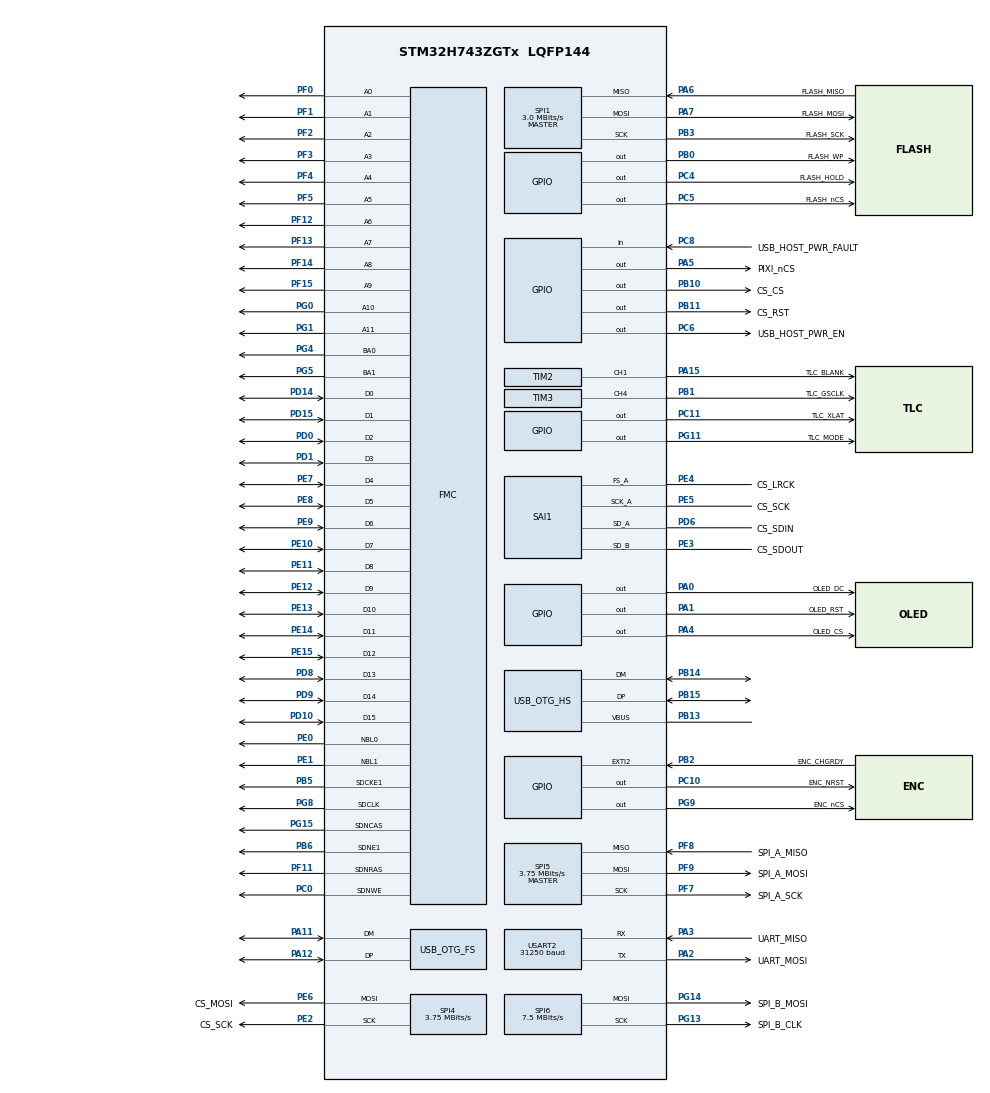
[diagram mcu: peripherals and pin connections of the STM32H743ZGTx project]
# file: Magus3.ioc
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Bdma.Request0=SPI6_TX
Bdma.RequestsNb=1
Bdma.SPI6_TX.0.Direction=DMA_MEMORY_TO_PERIPH
Bdma.SPI6_TX.0.EventEnable=DISABLE
Bdma.SPI6_TX.0.Instance=BDMA_Channel0
Bdma.SPI6_TX.0.MemDataAlignment=DMA_MDATAALIGN_BYTE
Bdma.SPI6_TX.0.MemInc=DMA_MINC_ENABLE
Bdma.SPI6_TX.0.Mode=DMA_NORMAL
Bdma.SPI6_TX.0.PeriphDataAlignment=DMA_PDATAALIGN_BYTE
Bdma.SPI6_TX.0.PeriphInc=DMA_PINC_DISABLE
Bdma.SPI6_TX.0.Polarity=HAL_DMAMUX_REQ_GEN_RISING
Bdma.SPI6_TX.0.Priority=DMA_PRIORITY_LOW
Bdma.SPI6_TX.0.RequestNumber=1
Bdma.SPI6_TX.0.SignalID=NONE
Bdma.SPI6_TX.0.SyncEnable=DISABLE
Bdma.SPI6_TX.0.SyncPolarity=HAL_DMAMUX_SYNC_NO_EVENT
Bdma.SPI6_TX.0.SyncRequestNumber=1
Bdma.SPI6_TX.0.SyncSignalID=NONE
Dma.Request0=SAI1_A
Dma.Request1=SAI1_B
Dma.Request2=SPI5_TX
Dma.Request3=USART2_TX
Dma.Request4=USART2_RX
Dma.SAI1_A.0.Direction=DMA_MEMORY_TO_PERIPH
Dma.SAI1_A.0.EventEnable=DISABLE
Dma.SAI1_A.0.FIFOMode=DMA_FIFOMODE_DISABLE
Dma.SAI1_A.0.Instance=DMA2_Stream1
Dma.SAI1_A.0.MemDataAlignment=DMA_MDATAALIGN_WORD
Dma.SAI1_A.0.MemInc=DMA_MINC_ENABLE
Dma.SAI1_A.0.Mode=DMA_CIRCULAR
Dma.SAI1_A.0.PeriphDataAlignment=DMA_PDATAALIGN_WORD
Dma.SAI1_A.0.PeriphInc=DMA_PINC_DISABLE
Dma.SAI1_A.0.Polarity=HAL_DMAMUX_REQ_GEN_RISING
Dma.SAI1_A.0.Priority=DMA_PRIORITY_VERY_HIGH
Dma.SAI1_A.0.RequestNumber=1
Dma.SAI1_A.0.SignalID=NONE
Dma.SAI1_A.0.SyncEnable=DISABLE
Dma.SAI1_A.0.SyncPolarity=HAL_DMAMUX_SYNC_NO_EVENT
Dma.SAI1_A.0.SyncRequestNumber=1
Dma.SAI1_A.0.SyncSignalID=NONE
Dma.SAI1_B.1.Direction=DMA_PERIPH_TO_MEMORY
Dma.SAI1_B.1.EventEnable=DISABLE
Dma.SAI1_B.1.FIFOMode=DMA_FIFOMODE_DISABLE
Dma.SAI1_B.1.Instance=DMA2_Stream4
Dma.SAI1_B.1.MemDataAlignment=DMA_MDATAALIGN_WORD
Dma.SAI1_B.1.MemInc=DMA_MINC_ENABLE
Dma.SAI1_B.1.Mode=DMA_CIRCULAR
Dma.SAI1_B.1.PeriphDataAlignment=DMA_PDATAALIGN_WORD
Dma.SAI1_B.1.PeriphInc=DMA_PINC_DISABLE
Dma.SAI1_B.1.Polarity=HAL_DMAMUX_REQ_GEN_RISING
Dma.SAI1_B.1.Priority=DMA_PRIORITY_VERY_HIGH
Dma.SAI1_B.1.RequestNumber=1
Dma.SAI1_B.1.SignalID=NONE
Dma.SAI1_B.1.SyncEnable=DISABLE
Dma.SAI1_B.1.SyncPolarity=HAL_DMAMUX_SYNC_NO_EVENT
Dma.SAI1_B.1.SyncRequestNumber=1
Dma.SAI1_B.1.SyncSignalID=NONE
Dma.SPI5_TX.2.Direction=DMA_MEMORY_TO_PERIPH
Dma.SPI5_TX.2.EventEnable=DISABLE
Dma.SPI5_TX.2.FIFOMode=DMA_FIFOMODE_DISABLE
Dma.SPI5_TX.2.Instance=DMA2_Stream6
Dma.SPI5_TX.2.MemDataAlignment=DMA_MDATAALIGN_BYTE
Dma.SPI5_TX.2.MemInc=DMA_MINC_ENABLE
Dma.SPI5_TX.2.Mode=DMA_NORMAL
Dma.SPI5_TX.2.PeriphDataAlignment=DMA_PDATAALIGN_BYTE
Dma.SPI5_TX.2.PeriphInc=DMA_PINC_DISABLE
Dma.SPI5_TX.2.Polarity=HAL_DMAMUX_REQ_GEN_RISING
Dma.SPI5_TX.2.Priority=DMA_PRIORITY_LOW
Dma.SPI5_TX.2.RequestNumber=1
Dma.SPI5_TX.2.SignalID=NONE
Dma.SPI5_TX.2.SyncEnable=DISABLE
Dma.SPI5_TX.2.SyncPolarity=HAL_DMAMUX_SYNC_NO_EVENT
Dma.SPI5_TX.2.SyncRequestNumber=1
Dma.SPI5_TX.2.SyncSignalID=NONE
Dma.USART2_RX.4.Direction=DMA_PERIPH_TO_MEMORY
Dma.USART2_RX.4.EventEnable=DISABLE
Dma.USART2_RX.4.FIFOMode=DMA_FIFOMODE_DISABLE
Dma.USART2_RX.4.Instance=DMA1_Stream5
Dma.USART2_RX.4.MemDataAlignment=DMA_MDATAALIGN_BYTE
Dma.USART2_RX.4.MemInc=DMA_MINC_ENABLE
Dma.USART2_RX.4.Mode=DMA_NORMAL
Dma.USART2_RX.4.PeriphDataAlignment=DMA_PDATAALIGN_BYTE
Dma.USART2_RX.4.PeriphInc=DMA_PINC_DISABLE
Dma.USART2_RX.4.Polarity=HAL_DMAMUX_REQ_GEN_RISING
Dma.USART2_RX.4.Priority=DMA_PRIORITY_LOW
Dma.USART2_RX.4.RequestNumber=1
Dma.USART2_RX.4.SignalID=NONE
Dma.USART2_RX.4.SyncEnable=DISABLE
Dma.USART2_RX.4.SyncPolarity=HAL_DMAMUX_SYNC_NO_EVENT
Dma.USART2_RX.4.SyncRequestNumber=1
Dma.USART2_RX.4.SyncSignalID=NONE
Dma.USART2_TX.3.Direction=DMA_MEMORY_TO_PERIPH
Dma.USART2_TX.3.EventEnable=DISABLE
Dma.USART2_TX.3.FIFOMode=DMA_FIFOMODE_DISABLE
Dma.USART2_TX.3.Instance=DMA1_Stream6
Dma.USART2_TX.3.MemDataAlignment=DMA_MDATAALIGN_BYTE
Dma.USART2_TX.3.MemInc=DMA_MINC_ENABLE
Dma.USART2_TX.3.Mode=DMA_NORMAL
Dma.USART2_TX.3.PeriphDataAlignment=DMA_PDATAALIGN_BYTE
Dma.USART2_TX.3.PeriphInc=DMA_PINC_DISABLE
Dma.USART2_TX.3.Polarity=HAL_DMAMUX_REQ_GEN_RISING
Dma.USART2_TX.3.Priority=DMA_PRIORITY_LOW
Dma.USART2_TX.3.RequestNumber=1
Dma.USART2_TX.3.SignalID=NONE
Dma.USART2_TX.3.SyncEnable=DISABLE
Dma.USART2_TX.3.SyncPolarity=HAL_DMAMUX_SYNC_NO_EVENT
Dma.USART2_TX.3.SyncRequestNumber=1
Dma.USART2_TX.3.SyncSignalID=NONE
FMC.CASLatency1=FMC_SDRAM_CAS_LATENCY_3
FMC.ExitSelfRefreshDelay1=6
FMC.LoadToActiveDelay1=2
FMC.RCDDelay1=2
FMC.RPDelay1=2
FMC.RPDelay2=2
FMC.ReadBurst1=FMC_SDRAM_RBURST_ENABLE
FMC.ReadBurst2=FMC_SDRAM_RBURST_ENABLE
FMC.ReadPipeDelay1=FMC_SDRAM_RPIPE_DELAY_0
FMC.RowCycleDelay1=6
FMC.RowCycleDelay2=6
FMC.SDClockPeriod1=FMC_SDRAM_CLOCK_PERIOD_2
FMC.SDClockPeriod2=FMC_SDRAM_CLOCK_PERIOD_2
FMC.SelfRefreshTime1=4
FMC.WriteRecoveryTime1=2
FREERTOS.INCLUDE_vTaskDelayUntil=1
FREERTOS.MEMORY_ALLOCATION=2
FREERTOS.Tasks01=defaultTask,0,1024,StartDefaultTask,Default,NULL,Dynamic,NULL,NULL
FREERTOS.configCHECK_FOR_STACK_OVERFLOW=2
FREERTOS.configUSE_MALLOC_FAILED_HOOK=1
FREERTOS.configUSE_MUTEXES=0
FREERTOS.configUSE_PREEMPTION=0
Mcu.Family=STM32H7
Mcu.Name=STM32H743ZGTx
Mcu.Package=LQFP144
NVIC.BDMA_Channel0_IRQn=true\:5\:0\:false\:false\:true\:true\:false\:true
NVIC.DMA1_Stream5_IRQn=true\:5\:0\:false\:false\:true\:true\:false\:true
NVIC.DMA1_Stream6_IRQn=true\:5\:0\:false\:false\:true\:true\:false\:true
NVIC.DMA2_Stream1_IRQn=true\:5\:0\:true\:false\:true\:true\:true\:true
NVIC.DMA2_Stream4_IRQn=true\:5\:0\:true\:false\:true\:true\:true\:true
NVIC.DMA2_Stream6_IRQn=true\:5\:0\:false\:false\:true\:true\:false\:true
NVIC.EXTI2_IRQn=true\:5\:0\:false\:false\:true\:true\:true\:true
NVIC.OTG_FS_IRQn=true\:10\:0\:true\:false\:true\:true\:true\:true
NVIC.OTG_HS_IRQn=true\:10\:0\:true\:false\:true\:true\:true\:true
NVIC.PriorityGroup=NVIC_PRIORITYGROUP_4
NVIC.SPI5_IRQn=true\:10\:0\:true\:false\:true\:true\:true\:true
NVIC.SPI6_IRQn=true\:5\:0\:false\:false\:true\:true\:true\:true
NVIC.USART2_IRQn=true\:5\:0\:false\:false\:true\:true\:true\:true
PA0.GPIO_Label=OLED_DC
PA0.Signal=GPIO_Output
PA1.GPIO_Label=OLED_RST
PA1.Signal=GPIO_Output
PA11.Mode=Device_Only
PA11.Signal=USB_OTG_FS_DM
PA12.Mode=Device_Only
PA12.Signal=USB_OTG_FS_DP
PA13\ (JTMS/SWDIO).Mode=Serial_Wire
PA13\ (JTMS/SWDIO).Signal=DEBUG_JTMS-SWDIO
PA14\ (JTCK/SWCLK).Mode=Serial_Wire
PA14\ (JTCK/SWCLK).Signal=DEBUG_JTCK-SWCLK
PA15\ (JTDI).GPIO_Label=TLC_BLANK
PA15\ (JTDI).GPIO_Speed=GPIO_SPEED_FREQ_VERY_HIGH
PA15\ (JTDI).Signal=S_TIM2_CH1
PA2.GPIO_Label=UART_MOSI
PA2.GPIO_Speed=GPIO_SPEED_FREQ_MEDIUM
PA2.Mode=Asynchronous
PA2.Signal=USART2_TX
PA3.GPIO_Label=UART_MISO
PA3.GPIO_Speed=GPIO_SPEED_FREQ_MEDIUM
PA3.Mode=Asynchronous
PA3.Signal=USART2_RX
PA4.GPIO_Label=OLED_CS
PA4.Signal=GPIO_Output
PA5.GPIO_Label=PIXI_nCS
PA5.Signal=GPIO_Output
PA6.GPIO_Label=FLASH_MISO
PA6.GPIO_Speed=GPIO_SPEED_FREQ_VERY_HIGH
PA6.Mode=Full_Duplex_Master
PA6.Signal=SPI1_MISO
PA7.GPIO_Label=FLASH_MOSI
PA7.GPIO_Speed=GPIO_SPEED_FREQ_VERY_HIGH
PA7.Mode=Full_Duplex_Master
PA7.Signal=SPI1_MOSI
PB0.GPIO_Label=FLASH_WP
PB0.Signal=GPIO_Output
PB1.GPIO_Label=TLC_GSCLK
PB1.GPIO_Speed=GPIO_SPEED_FREQ_VERY_HIGH
PB1.Signal=S_TIM3_CH4
PB10.GPIO_Label=CS_CS
PB10.Signal=GPIO_Output
PB11.GPIO_Label=CS_RST
PB11.Signal=GPIO_Output
PB13.Mode=Activate_VBUS_FS
PB13.Signal=USB_OTG_HS_VBUS
PB14.Mode=Host_FS
PB14.Signal=USB_OTG_HS_DM
PB15.Mode=Host_FS
PB15.Signal=USB_OTG_HS_DP
PB2.GPIO_Label=ENC_CHGRDY
PB2.Signal=GPXTI2
PB3\ (JTDO/TRACESWO).GPIO_Label=FLASH_SCK
PB3\ (JTDO/TRACESWO).GPIO_Speed=GPIO_SPEED_FREQ_VERY_HIGH
PB3\ (JTDO/TRACESWO).Mode=Full_Duplex_Master
PB3\ (JTDO/TRACESWO).Signal=SPI1_SCK
PB5.Mode=SdramChipSelect2_1
PB5.Signal=FMC_SDCKE1
PB6.Mode=SdramChipSelect2_1
PB6.Signal=FMC_SDNE1
PC0.Signal=FMC_SDNWE
PC10.GPIO_Label=ENC_NRST
PC10.GPIO_PuPd=GPIO_PULLUP
PC10.Signal=GPIO_Output
PC11.GPIO_Label=TLC_XLAT
PC11.Signal=GPIO_Output
PC4.GPIO_Label=FLASH_HOLD
PC4.Signal=GPIO_Output
PC5.GPIO_Label=FLASH_nCS
PC5.Signal=GPIO_Output
PC6.GPIO_Label=USB_HOST_PWR_EN
PC6.PinState=GPIO_PIN_SET
PC6.Signal=GPIO_Output
PC8.GPIO_Label=USB_HOST_PWR_FAULT
PC8.GPIO_PuPd=GPIO_PULLUP
PC8.Signal=GPIO_Input
PD0.Signal=FMC_D2_DA2
PD1.Signal=FMC_D3_DA3
PD10.Signal=FMC_D15_DA15
PD14.Signal=FMC_D0_DA0
PD15.Signal=FMC_D1_DA1
PD6.GPIO_Label=CS_SDIN
PD6.Mode=SAI_A_AsyncSlave
PD6.Signal=SAI1_SD_A
PD8.Signal=FMC_D13_DA13
PD9.Signal=FMC_D14_DA14
PE0.Signal=FMC_NBL0
PE1.Signal=FMC_NBL1
PE10.Signal=FMC_D7_DA7
PE11.Signal=FMC_D8_DA8
PE12.Signal=FMC_D9_DA9
PE13.Signal=FMC_D10_DA10
PE14.Signal=FMC_D11_DA11
PE15.Signal=FMC_D12_DA12
PE2.GPIO_Label=CS_SCK
PE2.Mode=TX_Only_Simplex_Unidirect_Master
PE2.Signal=SPI4_SCK
PE3.GPIO_Label=CS_SDOUT
PE3.Mode=SAI_B_SyncSlave
PE3.Signal=SAI1_SD_B
PE4.GPIO_Label=CS_LRCK
PE4.Mode=SAI_A_AsyncSlave
PE4.Signal=SAI1_FS_A
PE5.GPIO_Label=CS_SCK
PE5.Mode=SAI_A_AsyncSlave
PE5.Signal=SAI1_SCK_A
PE6.GPIO_Label=CS_MOSI
PE6.Mode=TX_Only_Simplex_Unidirect_Master
PE6.Signal=SPI4_MOSI
PE7.Signal=FMC_D4_DA4
PE8.Signal=FMC_D5_DA5
PE9.Signal=FMC_D6_DA6
PF0.Signal=FMC_A0
PF1.Signal=FMC_A1
PF11.Signal=FMC_SDNRAS
PF12.Signal=FMC_A6
PF13.Signal=FMC_A7
PF14.Signal=FMC_A8
PF15.Signal=FMC_A9
PF2.Signal=FMC_A2
PF3.Signal=FMC_A3
PF4.Signal=FMC_A4
PF5.Signal=FMC_A5
PF7.GPIO_Label=SPI_A_SCK
PF7.GPIO_Speed=GPIO_SPEED_FREQ_VERY_HIGH
PF7.Mode=Full_Duplex_Master
PF7.Signal=SPI5_SCK
PF8.GPIO_Label=SPI_A_MISO
PF8.GPIO_Speed=GPIO_SPEED_FREQ_VERY_HIGH
PF8.Mode=Full_Duplex_Master
PF8.Signal=SPI5_MISO
PF9.GPIO_Label=SPI_A_MOSI
PF9.GPIO_Speed=GPIO_SPEED_FREQ_VERY_HIGH
PF9.Mode=Full_Duplex_Master
PF9.Signal=SPI5_MOSI
PG0.Signal=FMC_A10
PG1.Signal=FMC_A11
PG11.GPIO_Label=TLC_MODE
PG11.Signal=GPIO_Output
PG13.GPIO_Label=SPI_B_CLK
PG13.Mode=TX_Only_Simplex_Unidirect_Master
PG13.Signal=SPI6_SCK
PG14.GPIO_Label=SPI_B_MOSI
PG14.Mode=TX_Only_Simplex_Unidirect_Master
PG14.Signal=SPI6_MOSI
PG15.Signal=FMC_SDNCAS
PG4.Signal=FMC_A14_BA0
PG5.Signal=FMC_A15_BA1
PG8.Signal=FMC_SDCLK
PG9.GPIO_Label=ENC_nCS
PG9.Signal=GPIO_Output
PH0-OSC_IN\ (PH0).GPIO_Label=OSC1
PH0-OSC_IN\ (PH0).Mode=HSE-External-Oscillator
PH0-OSC_IN\ (PH0).Signal=RCC_OSC_IN
PH1-OSC_OUT\ (PH1).GPIO_Label=OSC2
PH1-OSC_OUT\ (PH1).Mode=HSE-External-Oscillator
PH1-OSC_OUT\ (PH1).Signal=RCC_OSC_OUT
ProjectManager.HeapSize=0x200
ProjectManager.StackSize=0x400
ProjectManager.TargetToolchain=Other Toolchains (GPDSC)
RCC.48MHZClocksFreq_Value=48000000
RCC.ADCFreq_Value=30000000
RCC.AHBFreq_Value=168000000
RCC.APB1CLKDivider=RCC_HCLK_DIV4
RCC.APB1Freq_Value=120000000
RCC.APB1TimFreq_Value=84000000
RCC.APB2CLKDivider=RCC_HCLK_DIV2
RCC.APB2Freq_Value=120000000
RCC.APB2TimFreq_Value=168000000
RCC.APB3Freq_Value=120000000
RCC.APB4Freq_Value=120000000
RCC.CortexFreq_Value=480000000
RCC.D1PPRE=RCC_APB3_DIV2
RCC.D2PPRE1=RCC_APB1_DIV2
RCC.D2PPRE2=RCC_APB2_DIV2
RCC.D3PPRE=RCC_APB4_DIV2
RCC.DIVM1=5
RCC.DIVM2=2
RCC.DIVN1=192
RCC.DIVN2=12
RCC.DIVP2=5
RCC.DIVQ1=20
RCC.HCLKFreq_Value=240000000
RCC.HPRE=RCC_HCLK_DIV2
RCC.HSE_VALUE=25000000
RCC.HSI_VALUE=16000000
RCC.LSE_VALUE=32768
RCC.PLLM=25
RCC.PLLN=336
RCC.PLLQ=7
RCC.PLLSAIN=100
RCC.PWR_Regulator_Voltage_Scale=PWR_REGULATOR_VOLTAGE_SCALE0
RCC.ProductRev=revV
RCC.SAI1CLockSelection=RCC_SAI1CLKSOURCE_PLL2
RCC.SYSCLKFreq_VALUE=480000000
RCC.SYSCLKSource=RCC_SYSCLKSOURCE_PLLCLK
RCC.USBFreq_Value=48000000
RCC.VCOOutputFreq_Value=336000000
SAI1.AudioMode-SAI_A_AsyncSlave=SAI_MODESLAVE_TX
SAI1.AudioMode-SAI_B_SyncSlave=SAI_MODESLAVE_RX
SAI1.BasicDataSize-SAI_A_AsyncSlave=SAI_PROTOCOL_DATASIZE_24BIT
SAI1.BasicDataSize-SAI_B_SyncSlave=SAI_PROTOCOL_DATASIZE_24BIT
SAI1.InitProtocol-SAI_A_AsyncSlave=Enable
SAI1.InitProtocol-SAI_B_SyncSlave=Enable
SAI1.Instance-SAI_A_AsyncSlave=SAI$Index_Block_A
SAI1.Instance-SAI_B_SyncSlave=SAI$Index_Block_B
SAI1.Synchro_A=SAI_ASYNCHRONOUS
SAI1.Synchro_B=SAI_SYNCHRONOUS
SAI1.VirtualMode-SAI_A_AsyncSlave=VM_SLAVE
SAI1.VirtualMode-SAI_B_SyncSlave=VM_SLAVE
SAI1.VirtualProtocol-SAI_A_BASIC=VM_BASIC_PROTOCOL
SAI1.VirtualProtocol-SAI_B_BASIC=VM_BASIC_PROTOCOL
SH.FMC_A0.0=FMC_A0,12b-sda1
SH.FMC_A1.0=FMC_A1,12b-sda1
SH.FMC_A10.0=FMC_A10,12b-sda1
SH.FMC_A11.0=FMC_A11,12b-sda1
SH.FMC_A14_BA0.0=FMC_BA0,FourSdramBanks1
SH.FMC_A15_BA1.0=FMC_BA1,FourSdramBanks1
SH.FMC_A2.0=FMC_A2,12b-sda1
SH.FMC_A3.0=FMC_A3,12b-sda1
SH.FMC_A4.0=FMC_A4,12b-sda1
SH.FMC_A5.0=FMC_A5,12b-sda1
SH.FMC_A6.0=FMC_A6,12b-sda1
SH.FMC_A7.0=FMC_A7,12b-sda1
SH.FMC_A8.0=FMC_A8,12b-sda1
SH.FMC_A9.0=FMC_A9,12b-sda1
SH.FMC_D0_DA0.0=FMC_D0,sd-16b-d1
SH.FMC_D10_DA10.0=FMC_D10,sd-16b-d1
SH.FMC_D11_DA11.0=FMC_D11,sd-16b-d1
SH.FMC_D12_DA12.0=FMC_D12,sd-16b-d1
SH.FMC_D13_DA13.0=FMC_D13,sd-16b-d1
SH.FMC_D14_DA14.0=FMC_D14,sd-16b-d1
SH.FMC_D15_DA15.0=FMC_D15,sd-16b-d1
SH.FMC_D1_DA1.0=FMC_D1,sd-16b-d1
SH.FMC_D2_DA2.0=FMC_D2,sd-16b-d1
SH.FMC_D3_DA3.0=FMC_D3,sd-16b-d1
SH.FMC_D4_DA4.0=FMC_D4,sd-16b-d1
SH.FMC_D5_DA5.0=FMC_D5,sd-16b-d1
SH.FMC_D6_DA6.0=FMC_D6,sd-16b-d1
SH.FMC_D7_DA7.0=FMC_D7,sd-16b-d1
SH.FMC_D8_DA8.0=FMC_D8,sd-16b-d1
SH.FMC_D9_DA9.0=FMC_D9,sd-16b-d1
SH.FMC_NBL0.0=FMC_NBL0,Sd2ByteEnable1
SH.FMC_NBL1.0=FMC_NBL1,Sd2ByteEnable1
SH.FMC_SDCLK.0=FMC_SDCLK,12b-sda1
SH.FMC_SDNCAS.0=FMC_SDNCAS,12b-sda1
SH.FMC_SDNRAS.0=FMC_SDNRAS,12b-sda1
SH.FMC_SDNWE.0=FMC_SDNWE,12b-sda1
SH.S_TIM2_CH1.0=TIM2_CH1,PWM Generation1 CH1
SH.S_TIM3_CH4.0=TIM3_CH4,PWM Generation4 CH4
SPI1.BaudRatePrescaler=SPI_BAUDRATEPRESCALER_16
SPI1.CalculateBaudRate=3.0 MBits/s
SPI1.DataSize=SPI_DATASIZE_8BIT
SPI1.Direction=SPI_DIRECTION_2LINES
SPI1.Mode=SPI_MODE_MASTER
SPI1.NSSPMode=SPI_NSS_PULSE_DISABLE
SPI1.VirtualType=VM_MASTER
SPI4.BaudRatePrescaler=SPI_BAUDRATEPRESCALER_32
SPI4.CalculateBaudRate=3.75 MBits/s
SPI4.DataSize=SPI_DATASIZE_8BIT
SPI4.Direction=SPI_DIRECTION_2LINES_TXONLY
SPI4.Mode=SPI_MODE_MASTER
SPI4.NSSPMode=SPI_NSS_PULSE_DISABLE
SPI4.VirtualType=VM_MASTER
SPI5.BaudRatePrescaler=SPI_BAUDRATEPRESCALER_32
SPI5.CalculateBaudRate=3.75 MBits/s
SPI5.DataSize=SPI_DATASIZE_8BIT
SPI5.Direction=SPI_DIRECTION_2LINES
SPI5.Mode=SPI_MODE_MASTER
SPI5.NSSPMode=SPI_NSS_PULSE_DISABLE
SPI5.VirtualType=VM_MASTER
SPI6.BaudRatePrescaler=SPI_BAUDRATEPRESCALER_16
SPI6.CalculateBaudRate=7.5 MBits/s
SPI6.DataSize=SPI_DATASIZE_8BIT
SPI6.Direction=SPI_DIRECTION_2LINES_TXONLY
SPI6.Mode=SPI_MODE_MASTER
SPI6.NSSPMode=SPI_NSS_PULSE_DISABLE
SPI6.VirtualType=VM_MASTER
TIM2.Channel-PWM\ Generation1\ CH1=TIM_CHANNEL_1
TIM2.ClockDivision=TIM_CLOCKDIVISION_DIV2
TIM2.Period=200
TIM2.Prescaler=4095
TIM2.Pulse-PWM\ Generation1\ CH1=100
TIM3.Channel-PWM\ Generation4\ CH4=TIM_CHANNEL_4
TIM3.ClockDivision=TIM_CLOCKDIVISION_DIV2
TIM3.OCFastMode_PWM-PWM\ Generation4\ CH4=TIM_OCFAST_DISABLE
TIM3.Period=100
TIM3.Pulse-PWM\ Generation4\ CH4=50
USART2.BaudRate=31250
USART2.Mode=MODE_TX_RX
USART2.VirtualMode=VM_ASYNC
USART2.VirtualMode-Asynchronous=VM_ASYNC
USB_OTG_FS.VirtualMode=Device_Only
USB_OTG_HS.VirtualMode-Host_FS=Host_FS
VP_FREERTOS_VS_CMSIS_V1.Mode=CMSIS_V1
VP_SAI1_VP_$IpInstance_SAIA_SAI_BASIC.Mode=SAI_A_BASIC
VP_SAI1_VP_$IpInstance_SAIB_SAI_BASIC.Mode=SAI_B_BASIC
board=Magus

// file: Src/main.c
/* USER CODE BEGIN Header */
/**
  ******************************************************************************
  * @file           : main.c
  * @brief          : Main program body
  ******************************************************************************
  * This notice applies to any and all portions of this file
  * that are not between comment pairs USER CODE BEGIN and
  * USER CODE END. Other portions of this file, whether
  * inserted by the user or by software development tools
  * are owned by their respective copyright owners.
  *
  * Copyright (c) 2018 STMicroelectronics International N.V.
  * All rights reserved.
  *
  * Redistribution and use in source and binary forms, with or without
  * modification, are permitted, provided that the following conditions are met:
  *
  * 1. Redistribution of source code must retain the above copyright notice,
  *    this list of conditions and the following disclaimer.
  * 2. Redistributions in binary form must reproduce the above copyright notice,
  *    this list of conditions and the following disclaimer in the documentation
  *    and/or other materials provided with the distribution.
  * 3. Neither the name of STMicroelectronics nor the names of other
  *    contributors to this software may be used to endorse or promote products
  *    derived from this software without specific written permission.
  * 4. This software, including modifications and/or derivative works of this
  *    software, must execute solely and exclusively on microcontroller or
  *    microprocessor devices manufactured by or for STMicroelectronics.
  * 5. Redistribution and use of this software other than as permitted under
  *    this license is void and will automatically terminate your rights under
  *    this license.
  *
  * THIS SOFTWARE IS PROVIDED BY STMICROELECTRONICS AND CONTRIBUTORS "AS IS"
  * AND ANY EXPRESS, IMPLIED OR STATUTORY WARRANTIES, INCLUDING, BUT NOT
  * LIMITED TO, THE IMPLIED WARRANTIES OF MERCHANTABILITY, FITNESS FOR A
  * PARTICULAR PURPOSE AND NON-INFRINGEMENT OF THIRD PARTY INTELLECTUAL PROPERTY
  * RIGHTS ARE DISCLAIMED TO THE FULLEST EXTENT PERMITTED BY LAW. IN NO EVENT
  * SHALL STMICROELECTRONICS OR CONTRIBUTORS BE LIABLE FOR ANY DIRECT, INDIRECT,
  * INCIDENTAL, SPECIAL, EXEMPLARY, OR CONSEQUENTIAL DAMAGES (INCLUDING, BUT NOT
  * LIMITED TO, PROCUREMENT OF SUBSTITUTE GOODS OR SERVICES; LOSS OF USE, DATA,
  * OR PROFITS; OR BUSINESS INTERRUPTION) HOWEVER CAUSED AND ON ANY THEORY OF
  * LIABILITY, WHETHER IN CONTRACT, STRICT LIABILITY, OR TORT (INCLUDING
  * NEGLIGENCE OR OTHERWISE) ARISING IN ANY WAY OUT OF THE USE OF THIS SOFTWARE,
  * EVEN IF ADVISED OF THE POSSIBILITY OF SUCH DAMAGE.
  *
  ******************************************************************************
  */
/* USER CODE END Header */
#include "main.h"
#include "cmsis_os.h"

/* USER CODE BEGIN Includes */
#include "device.h"
#include "errorhandlers.h"
/* USER CODE END Includes */

SAI_HandleTypeDef hsai_BlockA1;
SAI_HandleTypeDef hsai_BlockB1;
DMA_HandleTypeDef hdma_sai1_a;
DMA_HandleTypeDef hdma_sai1_b;

SPI_HandleTypeDef hspi1;
SPI_HandleTypeDef hspi4;
SPI_HandleTypeDef hspi5;
SPI_HandleTypeDef hspi6;
DMA_HandleTypeDef hdma_spi5_tx;
DMA_HandleTypeDef hdma_spi6_tx;

TIM_HandleTypeDef htim2;
TIM_HandleTypeDef htim3;

UART_HandleTypeDef huart2;
DMA_HandleTypeDef hdma_usart2_tx;
DMA_HandleTypeDef hdma_usart2_rx;

PCD_HandleTypeDef hpcd_USB_OTG_FS;
HCD_HandleTypeDef hhcd_USB_OTG_HS;

SDRAM_HandleTypeDef hsdram1;

osThreadId defaultTaskHandle;
/* USER CODE BEGIN PV */
/* Private variables ---------------------------------------------------------*/
/* USER CODE END PV */

void SystemClock_Config(void);
void PeriphCommonClock_Config(void);
static void MX_GPIO_Init(void);
static void MX_BDMA_Init(void);
static void MX_DMA_Init(void);
static void MX_FMC_Init(void);
static void MX_SAI1_Init(void);
static void MX_SPI4_Init(void);
static void MX_SPI1_Init(void);
static void MX_SPI5_Init(void);
static void MX_TIM3_Init(void);
static void MX_USART2_UART_Init(void);
static void MX_SPI6_Init(void);
static void MX_TIM2_Init(void);
static void MX_USB_OTG_FS_PCD_Init(void);
static void MX_USB_OTG_HS_HCD_Init(void);
void StartDefaultTask(void const * argument);

/* USER CODE BEGIN PFP */
/* Private function prototypes -----------------------------------------------*/
void setup(void);
void loop(void);
void SDRAM_Initialization_Sequence(SDRAM_HandleTypeDef *hsdram);
void initialise_monitor_handles(void);

/* USER CODE END PFP */

int main(void)
{
  /* USER CODE BEGIN 1 */
#ifdef DEBUG
#warning "DEBUG uses printf and semihosting!"
  if(CoreDebug->DHCSR & 0x01)
    initialise_monitor_handles(); // remove when not semi-hosting
  printf("showtime\n");
#endif
#ifdef USE_ICACHE
  /* Enable I-Cache-------------------------------------------------------------*/
  /* After reset, you must invalidate each cache before enabling (SCB_EnableICache) it. */
  SCB_InvalidateICache();
  SCB_EnableICache();
#endif
#ifdef USE_DCACHE
  /* Enable D-Cache-------------------------------------------------------------*/
  /* Before enabling the data cache, you must invalidate the entire data cache (SCB_InvalidateDCache), because external memory might have changed from when the cache was disabled. */
  SCB_InvalidateDCache();
  SCB_EnableDCache();
#endif

  /* Enable D2 domain SRAM Clocks */
  __HAL_RCC_D2SRAM1_CLK_ENABLE();
  __HAL_RCC_D2SRAM2_CLK_ENABLE();
  __HAL_RCC_D2SRAM3_CLK_ENABLE();

  /* USER CODE END 1 */

  /* MCU Configuration--------------------------------------------------------*/

  /* Reset of all peripherals, Initializes the Flash interface and the Systick. */
  HAL_Init();

  /* Configure the system clock */
  SystemClock_Config();

/* Configure the peripherals common clocks */
  PeriphCommonClock_Config();

  /* Initialize all configured peripherals */
  MX_GPIO_Init();
  MX_BDMA_Init();
  MX_DMA_Init();
  MX_FMC_Init();
  MX_SAI1_Init();
  MX_SPI4_Init();
  MX_SPI1_Init();
  MX_SPI5_Init();
  MX_TIM3_Init();
  MX_USART2_UART_Init();
  MX_SPI6_Init();
  MX_TIM2_Init();
  MX_USB_OTG_FS_PCD_Init();
  MX_USB_OTG_HS_HCD_Init();
  /* USER CODE BEGIN 2 */
  /* HAL_SAI_DeInit(&hsai_BlockA1); */
  /* HAL_SAI_DeInit(&hsai_BlockB1); */
  /* hsai_BlockA1.Instance = SAI1_Block_A; */
  /* hsai_BlockA1.Init.AudioMode = SAI_MODESLAVE_TX; */
  /* hsai_BlockA1.Init.Synchro = SAI_ASYNCHRONOUS; */
  /* hsai_BlockA1.Init.OutputDrive = SAI_OUTPUTDRIVE_DISABLE; */
  /* hsai_BlockA1.Init.FIFOThreshold = SAI_FIFOTHRESHOLD_EMPTY; */
  /* hsai_BlockA1.Init.SynchroExt = SAI_SYNCEXT_DISABLE; */
  /* hsai_BlockA1.Init.MonoStereoMode = SAI_STEREOMODE; */
  /* hsai_BlockA1.Init.CompandingMode = SAI_NOCOMPANDING; */
  /* hsai_BlockA1.Init.TriState = SAI_OUTPUT_NOTRELEASED; */
  /* if (HAL_SAI_InitProtocol(&hsai_BlockA1, SAI_I2S_STANDARD, SAI_PROTOCOL_DATASIZE_24BIT, 2) != HAL_OK) */
  /*   Error_Handler(); */
  /* hsai_BlockB1.Instance = SAI1_Block_B; */
  /* hsai_BlockB1.Init.AudioMode = SAI_MODESLAVE_RX; */
  /* hsai_BlockB1.Init.Synchro = SAI_SYNCHRONOUS; */
  /* hsai_BlockB1.Init.OutputDrive = SAI_OUTPUTDRIVE_DISABLE; */
  /* hsai_BlockB1.Init.FIFOThreshold = SAI_FIFOTHRESHOLD_EMPTY; */
  /* hsai_BlockB1.Init.SynchroExt = SAI_SYNCEXT_DISABLE; */
  /* hsai_BlockB1.Init.MonoStereoMode = SAI_STEREOMODE; */
  /* hsai_BlockB1.Init.CompandingMode = SAI_NOCOMPANDING; */
  /* hsai_BlockB1.Init.TriState = SAI_OUTPUT_NOTRELEASED; */
  /* if (HAL_SAI_InitProtocol(&hsai_BlockB1, SAI_I2S_STANDARD, SAI_PROTOCOL_DATASIZE_24BIT, 2) != HAL_OK) */
  /*   Error_Handler(); */

  /* HAL_NVIC_SetPriority(EXTI2_IRQn, 3, 0); */
  /* HAL_NVIC_EnableIRQ(EXTI2_IRQn); */

  SDRAM_Initialization_Sequence(&hsdram1);

  /* USER CODE END 2 */

  /* Create the thread(s) */
  /* definition and creation of defaultTask */
  osThreadDef(defaultTask, StartDefaultTask, osPriorityNormal, 0, 1024);
  defaultTaskHandle = osThreadCreate(osThread(defaultTask), NULL);

  /* Start scheduler */
  osKernelStart();

  /* We should never get here as control is now taken by the scheduler */
  /* Infinite loop */
  while (1)
  {

  }
}

void SystemClock_Config(void)
{
  RCC_OscInitTypeDef RCC_OscInitStruct = {0};
  RCC_ClkInitTypeDef RCC_ClkInitStruct = {0};

  /** Supply configuration update enable
  */
  HAL_PWREx_ConfigSupply(PWR_LDO_SUPPLY);
  /** Configure the main internal regulator output voltage
  */
  __HAL_PWR_VOLTAGESCALING_CONFIG(PWR_REGULATOR_VOLTAGE_SCALE0);

  while(!__HAL_PWR_GET_FLAG(PWR_FLAG_VOSRDY)) {}
  /** Macro to configure the PLL clock source
  */
  __HAL_RCC_PLL_PLLSOURCE_CONFIG(RCC_PLLSOURCE_HSE);
  /** Initializes the RCC Oscillators according to the specified parameters
  * in the RCC_OscInitTypeDef structure.
  */
  RCC_OscInitStruct.OscillatorType = RCC_OSCILLATORTYPE_HSE;
  RCC_OscInitStruct.HSEState = RCC_HSE_ON;
  RCC_OscInitStruct.PLL.PLLState = RCC_PLL_ON;
  RCC_OscInitStruct.PLL.PLLSource = RCC_PLLSOURCE_HSE;
  RCC_OscInitStruct.PLL.PLLM = 5;
  RCC_OscInitStruct.PLL.PLLN = 192;
  RCC_OscInitStruct.PLL.PLLP = 2;
  RCC_OscInitStruct.PLL.PLLQ = 20;
  RCC_OscInitStruct.PLL.PLLR = 2;
  RCC_OscInitStruct.PLL.PLLRGE = RCC_PLL1VCIRANGE_2;
  RCC_OscInitStruct.PLL.PLLVCOSEL = RCC_PLL1VCOWIDE;
  RCC_OscInitStruct.PLL.PLLFRACN = 0;
  if (HAL_RCC_OscConfig(&RCC_OscInitStruct) != HAL_OK)
  {
    Error_Handler();
  }
  /** Initializes the CPU, AHB and APB buses clocks
  */
  RCC_ClkInitStruct.ClockType = RCC_CLOCKTYPE_HCLK|RCC_CLOCKTYPE_SYSCLK
                              |RCC_CLOCKTYPE_PCLK1|RCC_CLOCKTYPE_PCLK2
                              |RCC_CLOCKTYPE_D3PCLK1|RCC_CLOCKTYPE_D1PCLK1;
  RCC_ClkInitStruct.SYSCLKSource = RCC_SYSCLKSOURCE_PLLCLK;
  RCC_ClkInitStruct.SYSCLKDivider = RCC_SYSCLK_DIV1;
  RCC_ClkInitStruct.AHBCLKDivider = RCC_HCLK_DIV2;
  RCC_ClkInitStruct.APB3CLKDivider = RCC_APB3_DIV2;
  RCC_ClkInitStruct.APB1CLKDivider = RCC_APB1_DIV2;
  RCC_ClkInitStruct.APB2CLKDivider = RCC_APB2_DIV2;
  RCC_ClkInitStruct.APB4CLKDivider = RCC_APB4_DIV2;

  if (HAL_RCC_ClockConfig(&RCC_ClkInitStruct, FLASH_LATENCY_4) != HAL_OK)
  {
    Error_Handler();
  }
}

void PeriphCommonClock_Config(void)
{
  RCC_PeriphCLKInitTypeDef PeriphClkInitStruct = {0};

  /** Initializes the peripherals clock
  */
  PeriphClkInitStruct.PeriphClockSelection = RCC_PERIPHCLK_SAI1;
  PeriphClkInitStruct.PLL2.PLL2M = 2;
  PeriphClkInitStruct.PLL2.PLL2N = 12;
  PeriphClkInitStruct.PLL2.PLL2P = 5;
  PeriphClkInitStruct.PLL2.PLL2Q = 2;
  PeriphClkInitStruct.PLL2.PLL2R = 2;
  PeriphClkInitStruct.PLL2.PLL2RGE = RCC_PLL2VCIRANGE_3;
  PeriphClkInitStruct.PLL2.PLL2VCOSEL = RCC_PLL2VCOMEDIUM;
  PeriphClkInitStruct.PLL2.PLL2FRACN = 0;
  PeriphClkInitStruct.Sai1ClockSelection = RCC_SAI1CLKSOURCE_PLL2;
  if (HAL_RCCEx_PeriphCLKConfig(&PeriphClkInitStruct) != HAL_OK)
  {
    Error_Handler();
  }
}

static void MX_SAI1_Init(void)
{

  hsai_BlockA1.Instance = SAI1_Block_A;
  hsai_BlockA1.Init.AudioMode = SAI_MODESLAVE_TX;
  hsai_BlockA1.Init.Synchro = SAI_ASYNCHRONOUS;
  hsai_BlockA1.Init.OutputDrive = SAI_OUTPUTDRIVE_DISABLE;
  hsai_BlockA1.Init.FIFOThreshold = SAI_FIFOTHRESHOLD_EMPTY;
  hsai_BlockA1.Init.SynchroExt = SAI_SYNCEXT_DISABLE;
  hsai_BlockA1.Init.MonoStereoMode = SAI_STEREOMODE;
  hsai_BlockA1.Init.CompandingMode = SAI_NOCOMPANDING;
  hsai_BlockA1.Init.TriState = SAI_OUTPUT_NOTRELEASED;
  if (HAL_SAI_InitProtocol(&hsai_BlockA1, SAI_I2S_STANDARD, SAI_PROTOCOL_DATASIZE_24BIT, 2) != HAL_OK)
  {
    Error_Handler();
  }
  hsai_BlockB1.Instance = SAI1_Block_B;
  hsai_BlockB1.Init.AudioMode = SAI_MODESLAVE_RX;
  hsai_BlockB1.Init.Synchro = SAI_SYNCHRONOUS;
  hsai_BlockB1.Init.OutputDrive = SAI_OUTPUTDRIVE_DISABLE;
  hsai_BlockB1.Init.FIFOThreshold = SAI_FIFOTHRESHOLD_EMPTY;
  hsai_BlockB1.Init.SynchroExt = SAI_SYNCEXT_DISABLE;
  hsai_BlockB1.Init.MonoStereoMode = SAI_STEREOMODE;
  hsai_BlockB1.Init.CompandingMode = SAI_NOCOMPANDING;
  hsai_BlockB1.Init.TriState = SAI_OUTPUT_NOTRELEASED;
  if (HAL_SAI_InitProtocol(&hsai_BlockB1, SAI_I2S_STANDARD, SAI_PROTOCOL_DATASIZE_24BIT, 2) != HAL_OK)
  {
    Error_Handler();
  }

}

static void MX_SPI1_Init(void)
{

  /* SPI1 parameter configuration*/
  hspi1.Instance = SPI1;
  hspi1.Init.Mode = SPI_MODE_MASTER;
  hspi1.Init.Direction = SPI_DIRECTION_2LINES;
  hspi1.Init.DataSize = SPI_DATASIZE_8BIT;
  hspi1.Init.CLKPolarity = SPI_POLARITY_LOW;
  hspi1.Init.CLKPhase = SPI_PHASE_1EDGE;
  hspi1.Init.NSS = SPI_NSS_SOFT;
  hspi1.Init.BaudRatePrescaler = SPI_BAUDRATEPRESCALER_16;
  hspi1.Init.FirstBit = SPI_FIRSTBIT_MSB;
  hspi1.Init.TIMode = SPI_TIMODE_DISABLE;
  hspi1.Init.CRCCalculation = SPI_CRCCALCULATION_DISABLE;
  hspi1.Init.CRCPolynomial = 0x0;
  hspi1.Init.NSSPMode = SPI_NSS_PULSE_DISABLE;
  hspi1.Init.NSSPolarity = SPI_NSS_POLARITY_LOW;
  hspi1.Init.FifoThreshold = SPI_FIFO_THRESHOLD_01DATA;
  hspi1.Init.TxCRCInitializationPattern = SPI_CRC_INITIALIZATION_ALL_ZERO_PATTERN;
  hspi1.Init.RxCRCInitializationPattern = SPI_CRC_INITIALIZATION_ALL_ZERO_PATTERN;
  hspi1.Init.MasterSSIdleness = SPI_MASTER_SS_IDLENESS_00CYCLE;
  hspi1.Init.MasterInterDataIdleness = SPI_MASTER_INTERDATA_IDLENESS_00CYCLE;
  hspi1.Init.MasterReceiverAutoSusp = SPI_MASTER_RX_AUTOSUSP_DISABLE;
  hspi1.Init.MasterKeepIOState = SPI_MASTER_KEEP_IO_STATE_DISABLE;
  hspi1.Init.IOSwap = SPI_IO_SWAP_DISABLE;
  if (HAL_SPI_Init(&hspi1) != HAL_OK)
  {
    Error_Handler();
  }

}

static void MX_SPI4_Init(void)
{

  /* SPI4 parameter configuration*/
  hspi4.Instance = SPI4;
  hspi4.Init.Mode = SPI_MODE_MASTER;
  hspi4.Init.Direction = SPI_DIRECTION_2LINES_TXONLY;
  hspi4.Init.DataSize = SPI_DATASIZE_8BIT;
  hspi4.Init.CLKPolarity = SPI_POLARITY_LOW;
  hspi4.Init.CLKPhase = SPI_PHASE_1EDGE;
  hspi4.Init.NSS = SPI_NSS_SOFT;
  hspi4.Init.BaudRatePrescaler = SPI_BAUDRATEPRESCALER_32;
  hspi4.Init.FirstBit = SPI_FIRSTBIT_MSB;
  hspi4.Init.TIMode = SPI_TIMODE_DISABLE;
  hspi4.Init.CRCCalculation = SPI_CRCCALCULATION_DISABLE;
  hspi4.Init.CRCPolynomial = 0x0;
  hspi4.Init.NSSPMode = SPI_NSS_PULSE_DISABLE;
  hspi4.Init.NSSPolarity = SPI_NSS_POLARITY_LOW;
  hspi4.Init.FifoThreshold = SPI_FIFO_THRESHOLD_01DATA;
  hspi4.Init.TxCRCInitializationPattern = SPI_CRC_INITIALIZATION_ALL_ZERO_PATTERN;
  hspi4.Init.RxCRCInitializationPattern = SPI_CRC_INITIALIZATION_ALL_ZERO_PATTERN;
  hspi4.Init.MasterSSIdleness = SPI_MASTER_SS_IDLENESS_00CYCLE;
  hspi4.Init.MasterInterDataIdleness = SPI_MASTER_INTERDATA_IDLENESS_00CYCLE;
  hspi4.Init.MasterReceiverAutoSusp = SPI_MASTER_RX_AUTOSUSP_DISABLE;
  hspi4.Init.MasterKeepIOState = SPI_MASTER_KEEP_IO_STATE_DISABLE;
  hspi4.Init.IOSwap = SPI_IO_SWAP_DISABLE;
  if (HAL_SPI_Init(&hspi4) != HAL_OK)
  {
    Error_Handler();
  }

}

static void MX_SPI5_Init(void)
{

  /* SPI5 parameter configuration*/
  hspi5.Instance = SPI5;
  hspi5.Init.Mode = SPI_MODE_MASTER;
  hspi5.Init.Direction = SPI_DIRECTION_2LINES;
  hspi5.Init.DataSize = SPI_DATASIZE_8BIT;
  hspi5.Init.CLKPolarity = SPI_POLARITY_LOW;
  hspi5.Init.CLKPhase = SPI_PHASE_1EDGE;
  hspi5.Init.NSS = SPI_NSS_SOFT;
  hspi5.Init.BaudRatePrescaler = SPI_BAUDRATEPRESCALER_32;
  hspi5.Init.FirstBit = SPI_FIRSTBIT_MSB;
  hspi5.Init.TIMode = SPI_TIMODE_DISABLE;
  hspi5.Init.CRCCalculation = SPI_CRCCALCULATION_DISABLE;
  hspi5.Init.CRCPolynomial = 0x0;
  hspi5.Init.NSSPMode = SPI_NSS_PULSE_DISABLE;
  hspi5.Init.NSSPolarity = SPI_NSS_POLARITY_LOW;
  hspi5.Init.FifoThreshold = SPI_FIFO_THRESHOLD_01DATA;
  hspi5.Init.TxCRCInitializationPattern = SPI_CRC_INITIALIZATION_ALL_ZERO_PATTERN;
  hspi5.Init.RxCRCInitializationPattern = SPI_CRC_INITIALIZATION_ALL_ZERO_PATTERN;
  hspi5.Init.MasterSSIdleness = SPI_MASTER_SS_IDLENESS_00CYCLE;
  hspi5.Init.MasterInterDataIdleness = SPI_MASTER_INTERDATA_IDLENESS_00CYCLE;
  hspi5.Init.MasterReceiverAutoSusp = SPI_MASTER_RX_AUTOSUSP_DISABLE;
  hspi5.Init.MasterKeepIOState = SPI_MASTER_KEEP_IO_STATE_DISABLE;
  hspi5.Init.IOSwap = SPI_IO_SWAP_DISABLE;
  if (HAL_SPI_Init(&hspi5) != HAL_OK)
  {
    Error_Handler();
  }

}

static void MX_SPI6_Init(void)
{

  /* SPI6 parameter configuration*/
  hspi6.Instance = SPI6;
  hspi6.Init.Mode = SPI_MODE_MASTER;
  hspi6.Init.Direction = SPI_DIRECTION_2LINES_TXONLY;
  hspi6.Init.DataSize = SPI_DATASIZE_8BIT;
  hspi6.Init.CLKPolarity = SPI_POLARITY_LOW;
  hspi6.Init.CLKPhase = SPI_PHASE_1EDGE;
  hspi6.Init.NSS = SPI_NSS_SOFT;
  hspi6.Init.BaudRatePrescaler = SPI_BAUDRATEPRESCALER_16;
  hspi6.Init.FirstBit = SPI_FIRSTBIT_MSB;
  hspi6.Init.TIMode = SPI_TIMODE_DISABLE;
  hspi6.Init.CRCCalculation = SPI_CRCCALCULATION_DISABLE;
  hspi6.Init.CRCPolynomial = 0x0;
  hspi6.Init.NSSPMode = SPI_NSS_PULSE_DISABLE;
  hspi6.Init.NSSPolarity = SPI_NSS_POLARITY_LOW;
  hspi6.Init.FifoThreshold = SPI_FIFO_THRESHOLD_01DATA;
  hspi6.Init.TxCRCInitializationPattern = SPI_CRC_INITIALIZATION_ALL_ZERO_PATTERN;
  hspi6.Init.RxCRCInitializationPattern = SPI_CRC_INITIALIZATION_ALL_ZERO_PATTERN;
  hspi6.Init.MasterSSIdleness = SPI_MASTER_SS_IDLENESS_00CYCLE;
  hspi6.Init.MasterInterDataIdleness = SPI_MASTER_INTERDATA_IDLENESS_00CYCLE;
  hspi6.Init.MasterReceiverAutoSusp = SPI_MASTER_RX_AUTOSUSP_DISABLE;
  hspi6.Init.MasterKeepIOState = SPI_MASTER_KEEP_IO_STATE_DISABLE;
  hspi6.Init.IOSwap = SPI_IO_SWAP_DISABLE;
  if (HAL_SPI_Init(&hspi6) != HAL_OK)
  {
    Error_Handler();
  }

}

static void MX_TIM2_Init(void)
{

  TIM_MasterConfigTypeDef sMasterConfig = {0};
  TIM_OC_InitTypeDef sConfigOC = {0};

  htim2.Instance = TIM2;
  htim2.Init.Prescaler = 4095;
  htim2.Init.CounterMode = TIM_COUNTERMODE_UP;
  htim2.Init.Period = 200;
  htim2.Init.ClockDivision = TIM_CLOCKDIVISION_DIV2;
  htim2.Init.AutoReloadPreload = TIM_AUTORELOAD_PRELOAD_DISABLE;
  if (HAL_TIM_PWM_Init(&htim2) != HAL_OK)
  {
    Error_Handler();
  }
  sMasterConfig.MasterOutputTrigger = TIM_TRGO_RESET;
  sMasterConfig.MasterSlaveMode = TIM_MASTERSLAVEMODE_DISABLE;
  if (HAL_TIMEx_MasterConfigSynchronization(&htim2, &sMasterConfig) != HAL_OK)
  {
    Error_Handler();
  }
  sConfigOC.OCMode = TIM_OCMODE_PWM1;
  sConfigOC.Pulse = 100;
  sConfigOC.OCPolarity = TIM_OCPOLARITY_HIGH;
  sConfigOC.OCFastMode = TIM_OCFAST_DISABLE;
  if (HAL_TIM_PWM_ConfigChannel(&htim2, &sConfigOC, TIM_CHANNEL_1) != HAL_OK)
  {
    Error_Handler();
  }
  HAL_TIM_MspPostInit(&htim2);

}

static void MX_TIM3_Init(void)
{

  TIM_MasterConfigTypeDef sMasterConfig = {0};
  TIM_OC_InitTypeDef sConfigOC = {0};

  htim3.Instance = TIM3;
  htim3.Init.Prescaler = 0;
  htim3.Init.CounterMode = TIM_COUNTERMODE_UP;
  htim3.Init.Period = 100;
  htim3.Init.ClockDivision = TIM_CLOCKDIVISION_DIV2;
  htim3.Init.AutoReloadPreload = TIM_AUTORELOAD_PRELOAD_DISABLE;
  if (HAL_TIM_PWM_Init(&htim3) != HAL_OK)
  {
    Error_Handler();
  }
  sMasterConfig.MasterOutputTrigger = TIM_TRGO_RESET;
  sMasterConfig.MasterSlaveMode = TIM_MASTERSLAVEMODE_DISABLE;
  if (HAL_TIMEx_MasterConfigSynchronization(&htim3, &sMasterConfig) != HAL_OK)
  {
    Error_Handler();
  }
  sConfigOC.OCMode = TIM_OCMODE_PWM1;
  sConfigOC.Pulse = 50;
  sConfigOC.OCPolarity = TIM_OCPOLARITY_HIGH;
  sConfigOC.OCFastMode = TIM_OCFAST_DISABLE;
  if (HAL_TIM_PWM_ConfigChannel(&htim3, &sConfigOC, TIM_CHANNEL_4) != HAL_OK)
  {
    Error_Handler();
  }
  HAL_TIM_MspPostInit(&htim3);

}

static void MX_USART2_UART_Init(void)
{

  huart2.Instance = USART2;
  huart2.Init.BaudRate = 31250;
  huart2.Init.WordLength = UART_WORDLENGTH_8B;
  huart2.Init.StopBits = UART_STOPBITS_1;
  huart2.Init.Parity = UART_PARITY_NONE;
  huart2.Init.Mode = UART_MODE_TX_RX;
  huart2.Init.HwFlowCtl = UART_HWCONTROL_NONE;
  huart2.Init.OverSampling = UART_OVERSAMPLING_16;
  huart2.Init.OneBitSampling = UART_ONE_BIT_SAMPLE_DISABLE;
  huart2.Init.ClockPrescaler = UART_PRESCALER_DIV1;
  huart2.AdvancedInit.AdvFeatureInit = UART_ADVFEATURE_NO_INIT;
  if (HAL_UART_Init(&huart2) != HAL_OK)
  {
    Error_Handler();
  }
  if (HAL_UARTEx_SetTxFifoThreshold(&huart2, UART_TXFIFO_THRESHOLD_1_8) != HAL_OK)
  {
    Error_Handler();
  }
  if (HAL_UARTEx_SetRxFifoThreshold(&huart2, UART_RXFIFO_THRESHOLD_1_8) != HAL_OK)
  {
    Error_Handler();
  }
  if (HAL_UARTEx_DisableFifoMode(&huart2) != HAL_OK)
  {
    Error_Handler();
  }

}

static void MX_USB_OTG_FS_PCD_Init(void)
{

  hpcd_USB_OTG_FS.Instance = USB_OTG_FS;
  hpcd_USB_OTG_FS.Init.dev_endpoints = 9;
  hpcd_USB_OTG_FS.Init.speed = PCD_SPEED_FULL;
  hpcd_USB_OTG_FS.Init.dma_enable = DISABLE;
  hpcd_USB_OTG_FS.Init.phy_itface = PCD_PHY_EMBEDDED;
  hpcd_USB_OTG_FS.Init.Sof_enable = DISABLE;
  hpcd_USB_OTG_FS.Init.low_power_enable = DISABLE;
  hpcd_USB_OTG_FS.Init.lpm_enable = DISABLE;
  hpcd_USB_OTG_FS.Init.battery_charging_enable = DISABLE;
  hpcd_USB_OTG_FS.Init.vbus_sensing_enable = DISABLE;
  hpcd_USB_OTG_FS.Init.use_dedicated_ep1 = DISABLE;
  if (HAL_PCD_Init(&hpcd_USB_OTG_FS) != HAL_OK)
  {
    Error_Handler();
  }

}

static void MX_USB_OTG_HS_HCD_Init(void)
{

  hhcd_USB_OTG_HS.Instance = USB_OTG_HS;
  hhcd_USB_OTG_HS.Init.Host_channels = 16;
  hhcd_USB_OTG_HS.Init.speed = HCD_SPEED_FULL;
  hhcd_USB_OTG_HS.Init.dma_enable = DISABLE;
  hhcd_USB_OTG_HS.Init.phy_itface = USB_OTG_EMBEDDED_PHY;
  hhcd_USB_OTG_HS.Init.Sof_enable = DISABLE;
  hhcd_USB_OTG_HS.Init.low_power_enable = DISABLE;
  hhcd_USB_OTG_HS.Init.use_external_vbus = DISABLE;
  if (HAL_HCD_Init(&hhcd_USB_OTG_HS) != HAL_OK)
  {
    Error_Handler();
  }

}

static void MX_BDMA_Init(void)
{

  /* DMA controller clock enable */
  __HAL_RCC_BDMA_CLK_ENABLE();

  /* DMA interrupt init */
  /* BDMA_Channel0_IRQn interrupt configuration */
  HAL_NVIC_SetPriority(BDMA_Channel0_IRQn, 5, 0);
  HAL_NVIC_EnableIRQ(BDMA_Channel0_IRQn);

}

static void MX_DMA_Init(void)
{

  /* DMA controller clock enable */
  __HAL_RCC_DMA2_CLK_ENABLE();
  __HAL_RCC_DMA1_CLK_ENABLE();

  /* DMA interrupt init */
  /* DMA1_Stream5_IRQn interrupt configuration */
  HAL_NVIC_SetPriority(DMA1_Stream5_IRQn, 5, 0);
  HAL_NVIC_EnableIRQ(DMA1_Stream5_IRQn);
  /* DMA1_Stream6_IRQn interrupt configuration */
  HAL_NVIC_SetPriority(DMA1_Stream6_IRQn, 5, 0);
  HAL_NVIC_EnableIRQ(DMA1_Stream6_IRQn);
  /* DMA2_Stream1_IRQn interrupt configuration */
  HAL_NVIC_SetPriority(DMA2_Stream1_IRQn, 5, 0);
  HAL_NVIC_EnableIRQ(DMA2_Stream1_IRQn);
  /* DMA2_Stream4_IRQn interrupt configuration */
  HAL_NVIC_SetPriority(DMA2_Stream4_IRQn, 5, 0);
  HAL_NVIC_EnableIRQ(DMA2_Stream4_IRQn);
  /* DMA2_Stream6_IRQn interrupt configuration */
  HAL_NVIC_SetPriority(DMA2_Stream6_IRQn, 5, 0);
  HAL_NVIC_EnableIRQ(DMA2_Stream6_IRQn);

}

/* FMC initialization function */
static void MX_FMC_Init(void)
{

  FMC_SDRAM_TimingTypeDef SdramTiming = {0};

  /** Perform the SDRAM1 memory initialization sequence
  */
  hsdram1.Instance = FMC_SDRAM_DEVICE;
  /* hsdram1.Init */
  hsdram1.Init.SDBank = FMC_SDRAM_BANK2;
  hsdram1.Init.ColumnBitsNumber = FMC_SDRAM_COLUMN_BITS_NUM_8;
  hsdram1.Init.RowBitsNumber = FMC_SDRAM_ROW_BITS_NUM_12;
  hsdram1.Init.MemoryDataWidth = FMC_SDRAM_MEM_BUS_WIDTH_16;
  hsdram1.Init.InternalBankNumber = FMC_SDRAM_INTERN_BANKS_NUM_4;
  hsdram1.Init.CASLatency = FMC_SDRAM_CAS_LATENCY_3;
  hsdram1.Init.WriteProtection = FMC_SDRAM_WRITE_PROTECTION_DISABLE;
  hsdram1.Init.SDClockPeriod = FMC_SDRAM_CLOCK_PERIOD_2;
  hsdram1.Init.ReadBurst = FMC_SDRAM_RBURST_ENABLE;
  hsdram1.Init.ReadPipeDelay = FMC_SDRAM_RPIPE_DELAY_0;
  /* SdramTiming */
  SdramTiming.LoadToActiveDelay = 2;
  SdramTiming.ExitSelfRefreshDelay = 6;
  SdramTiming.SelfRefreshTime = 4;
  SdramTiming.RowCycleDelay = 6;
  SdramTiming.WriteRecoveryTime = 2;
  SdramTiming.RPDelay = 2;
  SdramTiming.RCDDelay = 2;

  if (HAL_SDRAM_Init(&hsdram1, &SdramTiming) != HAL_OK)
  {
    Error_Handler( );
  }

}

static void MX_GPIO_Init(void)
{
  GPIO_InitTypeDef GPIO_InitStruct = {0};

  /* GPIO Ports Clock Enable */
  __HAL_RCC_GPIOE_CLK_ENABLE();
  __HAL_RCC_GPIOC_CLK_ENABLE();
  __HAL_RCC_GPIOF_CLK_ENABLE();
  __HAL_RCC_GPIOH_CLK_ENABLE();
  __HAL_RCC_GPIOA_CLK_ENABLE();
  __HAL_RCC_GPIOB_CLK_ENABLE();
  __HAL_RCC_GPIOG_CLK_ENABLE();
  __HAL_RCC_GPIOD_CLK_ENABLE();

  /*Configure GPIO pin Output Level */
  HAL_GPIO_WritePin(GPIOA, OLED_DC_Pin|OLED_RST_Pin|OLED_CS_Pin|PIXI_nCS_Pin, GPIO_PIN_RESET);

  /*Configure GPIO pin Output Level */
  HAL_GPIO_WritePin(GPIOC, FLASH_HOLD_Pin|FLASH_nCS_Pin|ENC_NRST_Pin|TLC_XLAT_Pin, GPIO_PIN_RESET);

  /*Configure GPIO pin Output Level */
  HAL_GPIO_WritePin(GPIOB, FLASH_WP_Pin|CS_CS_Pin|CS_RST_Pin, GPIO_PIN_RESET);

  /*Configure GPIO pin Output Level */
  HAL_GPIO_WritePin(USB_HOST_PWR_EN_GPIO_Port, USB_HOST_PWR_EN_Pin, GPIO_PIN_SET);

  /*Configure GPIO pin Output Level */
  HAL_GPIO_WritePin(GPIOG, ENC_nCS_Pin|TLC_MODE_Pin, GPIO_PIN_RESET);

  /*Configure GPIO pins : PC13 PC14 PC15 PC1
                           PC2 PC3 PC7 PC9
                           PC12 */
  GPIO_InitStruct.Pin = GPIO_PIN_13|GPIO_PIN_14|GPIO_PIN_15|GPIO_PIN_1
                          |GPIO_PIN_2|GPIO_PIN_3|GPIO_PIN_7|GPIO_PIN_9
                          |GPIO_PIN_12;
  GPIO_InitStruct.Mode = GPIO_MODE_ANALOG;
  GPIO_InitStruct.Pull = GPIO_NOPULL;
  HAL_GPIO_Init(GPIOC, &GPIO_InitStruct);

  /*Configure GPIO pins : PF6 PF10 */
  GPIO_InitStruct.Pin = GPIO_PIN_6|GPIO_PIN_10;
  GPIO_InitStruct.Mode = GPIO_MODE_ANALOG;
  GPIO_InitStruct.Pull = GPIO_NOPULL;
  HAL_GPIO_Init(GPIOF, &GPIO_InitStruct);

  /*Configure GPIO pins : OLED_DC_Pin OLED_RST_Pin OLED_CS_Pin PIXI_nCS_Pin */
  GPIO_InitStruct.Pin = OLED_DC_Pin|OLED_RST_Pin|OLED_CS_Pin|PIXI_nCS_Pin;
  GPIO_InitStruct.Mode = GPIO_MODE_OUTPUT_PP;
  GPIO_InitStruct.Pull = GPIO_NOPULL;
  GPIO_InitStruct.Speed = GPIO_SPEED_FREQ_LOW;
  HAL_GPIO_Init(GPIOA, &GPIO_InitStruct);

  /*Configure GPIO pins : FLASH_HOLD_Pin FLASH_nCS_Pin USB_HOST_PWR_EN_Pin TLC_XLAT_Pin */
  GPIO_InitStruct.Pin = FLASH_HOLD_Pin|FLASH_nCS_Pin|USB_HOST_PWR_EN_Pin|TLC_XLAT_Pin;
  GPIO_InitStruct.Mode = GPIO_MODE_OUTPUT_PP;
  GPIO_InitStruct.Pull = GPIO_NOPULL;
  GPIO_InitStruct.Speed = GPIO_SPEED_FREQ_LOW;
  HAL_GPIO_Init(GPIOC, &GPIO_InitStruct);

  /*Configure GPIO pins : FLASH_WP_Pin CS_CS_Pin CS_RST_Pin */
  GPIO_InitStruct.Pin = FLASH_WP_Pin|CS_CS_Pin|CS_RST_Pin;
  GPIO_InitStruct.Mode = GPIO_MODE_OUTPUT_PP;
  GPIO_InitStruct.Pull = GPIO_NOPULL;
  GPIO_InitStruct.Speed = GPIO_SPEED_FREQ_LOW;
  HAL_GPIO_Init(GPIOB, &GPIO_InitStruct);

  /*Configure GPIO pin : ENC_CHGRDY_Pin */
  GPIO_InitStruct.Pin = ENC_CHGRDY_Pin;
  GPIO_InitStruct.Mode = GPIO_MODE_IT_RISING;
  GPIO_InitStruct.Pull = GPIO_NOPULL;
  HAL_GPIO_Init(ENC_CHGRDY_GPIO_Port, &GPIO_InitStruct);

  /*Configure GPIO pins : PB12 PB4 PB7 PB8
                           PB9 */
  GPIO_InitStruct.Pin = GPIO_PIN_12|GPIO_PIN_4|GPIO_PIN_7|GPIO_PIN_8
                          |GPIO_PIN_9;
  GPIO_InitStruct.Mode = GPIO_MODE_ANALOG;
  GPIO_InitStruct.Pull = GPIO_NOPULL;
  HAL_GPIO_Init(GPIOB, &GPIO_InitStruct);

  /*Configure GPIO pins : PD11 PD12 PD13 PD2
                           PD3 PD4 PD5 PD7 */
  GPIO_InitStruct.Pin = GPIO_PIN_11|GPIO_PIN_12|GPIO_PIN_13|GPIO_PIN_2
                          |GPIO_PIN_3|GPIO_PIN_4|GPIO_PIN_5|GPIO_PIN_7;
  GPIO_InitStruct.Mode = GPIO_MODE_ANALOG;
  GPIO_InitStruct.Pull = GPIO_NOPULL;
  HAL_GPIO_Init(GPIOD, &GPIO_InitStruct);

  /*Configure GPIO pins : PG2 PG3 PG6 PG7
                           PG10 PG12 */
  GPIO_InitStruct.Pin = GPIO_PIN_2|GPIO_PIN_3|GPIO_PIN_6|GPIO_PIN_7
                          |GPIO_PIN_10|GPIO_PIN_12;
  GPIO_InitStruct.Mode = GPIO_MODE_ANALOG;
  GPIO_InitStruct.Pull = GPIO_NOPULL;
  HAL_GPIO_Init(GPIOG, &GPIO_InitStruct);

  /*Configure GPIO pin : USB_HOST_PWR_FAULT_Pin */
  GPIO_InitStruct.Pin = USB_HOST_PWR_FAULT_Pin;
  GPIO_InitStruct.Mode = GPIO_MODE_INPUT;
  GPIO_InitStruct.Pull = GPIO_PULLUP;
  HAL_GPIO_Init(USB_HOST_PWR_FAULT_GPIO_Port, &GPIO_InitStruct);

  /*Configure GPIO pins : PA8 PA9 PA10 */
  GPIO_InitStruct.Pin = GPIO_PIN_8|GPIO_PIN_9|GPIO_PIN_10;
  GPIO_InitStruct.Mode = GPIO_MODE_ANALOG;
  GPIO_InitStruct.Pull = GPIO_NOPULL;
  HAL_GPIO_Init(GPIOA, &GPIO_InitStruct);

  /*Configure GPIO pin : ENC_NRST_Pin */
  GPIO_InitStruct.Pin = ENC_NRST_Pin;
  GPIO_InitStruct.Mode = GPIO_MODE_OUTPUT_PP;
  GPIO_InitStruct.Pull = GPIO_PULLUP;
  GPIO_InitStruct.Speed = GPIO_SPEED_FREQ_LOW;
  HAL_GPIO_Init(ENC_NRST_GPIO_Port, &GPIO_InitStruct);

  /*Configure GPIO pins : ENC_nCS_Pin TLC_MODE_Pin */
  GPIO_InitStruct.Pin = ENC_nCS_Pin|TLC_MODE_Pin;
  GPIO_InitStruct.Mode = GPIO_MODE_OUTPUT_PP;
  GPIO_InitStruct.Pull = GPIO_NOPULL;
  GPIO_InitStruct.Speed = GPIO_SPEED_FREQ_LOW;
  HAL_GPIO_Init(GPIOG, &GPIO_InitStruct);

  /* EXTI interrupt init*/
  HAL_NVIC_SetPriority(EXTI2_IRQn, 5, 0);
  HAL_NVIC_EnableIRQ(EXTI2_IRQn);

}

void StartDefaultTask(void const * argument)
{
  /* USER CODE BEGIN 5 */
  setup();

  /* Infinite loop */
  for(;;)
  {
    loop();
  }
  /* USER CODE END 5 */
}

void Error_Handler(void)
{
  /* USER CODE BEGIN Error_Handler_Debug */
#ifdef DEBUG
  __asm__("BKPT");
#else
  NVIC_SystemReset();
#endif
  /* USER CODE END Error_Handler_Debug */
}

#ifdef  USE_FULL_ASSERT
/**
  * @brief  Reports the name of the source file and the source line number
  *         where the assert_param error has occurred.
  * @param  file: pointer to the source file name
  * @param  line: assert_param error line source number
  * @retval None
  */
void assert_failed(uint8_t *file, uint32_t line)
{
  /* USER CODE BEGIN 6 */
#ifdef DEBUG
  __asm__("BKPT");
#else
  NVIC_SystemReset();
#endif
  /* USER CODE END 6 */
}
#endif /* USE_FULL_ASSERT */

/************************ (C) COPYRIGHT STMicroelectronics *****END OF FILE****/

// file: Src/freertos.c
/* USER CODE BEGIN Header */
/**
  ******************************************************************************
  * File Name          : freertos.c
  * Description        : Code for freertos applications
  ******************************************************************************
  * This notice applies to any and all portions of this file
  * that are not between comment pairs USER CODE BEGIN and
  * USER CODE END. Other portions of this file, whether
  * inserted by the user or by software development tools
  * are owned by their respective copyright owners.
  *
  * Copyright (c) 2018 STMicroelectronics International N.V.
  * All rights reserved.
  *
  * Redistribution and use in source and binary forms, with or without
  * modification, are permitted, provided that the following conditions are met:
  *
  * 1. Redistribution of source code must retain the above copyright notice,
  *    this list of conditions and the following disclaimer.
  * 2. Redistributions in binary form must reproduce the above copyright notice,
  *    this list of conditions and the following disclaimer in the documentation
  *    and/or other materials provided with the distribution.
  * 3. Neither the name of STMicroelectronics nor the names of other
  *    contributors to this software may be used to endorse or promote products
  *    derived from this software without specific written permission.
  * 4. This software, including modifications and/or derivative works of this
  *    software, must execute solely and exclusively on microcontroller or
  *    microprocessor devices manufactured by or for STMicroelectronics.
  * 5. Redistribution and use of this software other than as permitted under
  *    this license is void and will automatically terminate your rights under
  *    this license.
  *
  * THIS SOFTWARE IS PROVIDED BY STMICROELECTRONICS AND CONTRIBUTORS "AS IS"
  * AND ANY EXPRESS, IMPLIED OR STATUTORY WARRANTIES, INCLUDING, BUT NOT
  * LIMITED TO, THE IMPLIED WARRANTIES OF MERCHANTABILITY, FITNESS FOR A
  * PARTICULAR PURPOSE AND NON-INFRINGEMENT OF THIRD PARTY INTELLECTUAL PROPERTY
  * RIGHTS ARE DISCLAIMED TO THE FULLEST EXTENT PERMITTED BY LAW. IN NO EVENT
  * SHALL STMICROELECTRONICS OR CONTRIBUTORS BE LIABLE FOR ANY DIRECT, INDIRECT,
  * INCIDENTAL, SPECIAL, EXEMPLARY, OR CONSEQUENTIAL DAMAGES (INCLUDING, BUT NOT
  * LIMITED TO, PROCUREMENT OF SUBSTITUTE GOODS OR SERVICES; LOSS OF USE, DATA,
  * OR PROFITS; OR BUSINESS INTERRUPTION) HOWEVER CAUSED AND ON ANY THEORY OF
  * LIABILITY, WHETHER IN CONTRACT, STRICT LIABILITY, OR TORT (INCLUDING
  * NEGLIGENCE OR OTHERWISE) ARISING IN ANY WAY OUT OF THE USE OF THIS SOFTWARE,
  * EVEN IF ADVISED OF THE POSSIBILITY OF SUCH DAMAGE.
  *
  ******************************************************************************
  */
/* USER CODE END Header */

#include "FreeRTOS.h"
#include "task.h"
#include "main.h"

/* GetIdleTaskMemory prototype (linked to static allocation support) */
void vApplicationGetIdleTaskMemory( StaticTask_t **ppxIdleTaskTCBBuffer, StackType_t **ppxIdleTaskStackBuffer, uint32_t *pulIdleTaskStackSize );

/* Hook prototypes */
void vApplicationStackOverflowHook(xTaskHandle xTask, signed char *pcTaskName);
void vApplicationMallocFailedHook(void);

/* USER CODE BEGIN 4 */
/* __weak void vApplicationStackOverflowHook(TaskHandle_t xTask, signed char *pcTaskName) */
/* { */
   /* Run time stack overflow checking is performed if
   configCHECK_FOR_STACK_OVERFLOW is defined to 1 or 2. This hook function is
   called if a stack overflow is detected. */
/* } */
/* USER CODE END 4 */

/* USER CODE BEGIN 5 */
/* __weak void vApplicationMallocFailedHook(void) */
/* { */
   /* vApplicationMallocFailedHook() will only be called if
   configUSE_MALLOC_FAILED_HOOK is set to 1 in FreeRTOSConfig.h. It is a hook
   function that will get called if a call to pvPortMalloc() fails.
   pvPortMalloc() is called internally by the kernel whenever a task, queue,
   timer or semaphore is created. It is also called by various parts of the
   demo application. If heap_1.c or heap_2.c are used, then the size of the
   heap available to pvPortMalloc() is defined by configTOTAL_HEAP_SIZE in
   FreeRTOSConfig.h, and the xPortGetFreeHeapSize() API function can be used
   to query the size of free heap space that remains (although it does not
   provide information on how the remaining heap might be fragmented). */
/* } */
/* USER CODE END 5 */

/* USER CODE BEGIN GET_IDLE_TASK_MEMORY */
static StaticTask_t xIdleTaskTCBBuffer;
static StackType_t xIdleStack[configMINIMAL_STACK_SIZE];

void vApplicationGetIdleTaskMemory( StaticTask_t **ppxIdleTaskTCBBuffer, StackType_t **ppxIdleTaskStackBuffer, uint32_t *pulIdleTaskStackSize )
{
  *ppxIdleTaskTCBBuffer = &xIdleTaskTCBBuffer;
  *ppxIdleTaskStackBuffer = &xIdleStack[0];
  *pulIdleTaskStackSize = configMINIMAL_STACK_SIZE;
  /* place for user code */
}
/* USER CODE END GET_IDLE_TASK_MEMORY */

/************************ (C) COPYRIGHT STMicroelectronics *****END OF FILE****/
